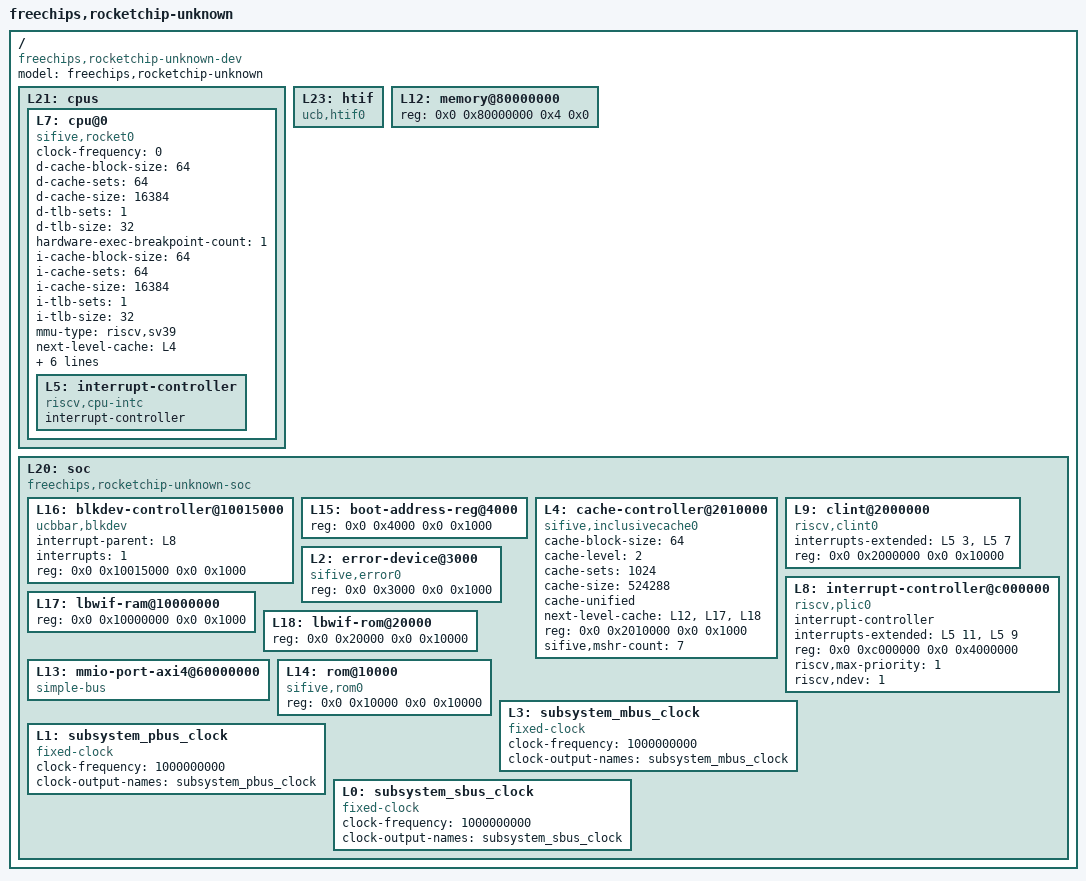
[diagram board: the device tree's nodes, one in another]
/dts-v1/;

/ {
	#address-cells = <2>;
	#size-cells = <2>;
	compatible = "freechips,rocketchip-unknown-dev";
	model = "freechips,rocketchip-unknown";
	L21: cpus {
		#address-cells = <1>;
		#size-cells = <0>;
		L7: cpu@0 {
			clock-frequency = <0>;
			compatible = "sifive,rocket0", "riscv";
			d-cache-block-size = <64>;
			d-cache-sets = <64>;
			d-cache-size = <16384>;
			d-tlb-sets = <1>;
			d-tlb-size = <32>;
			device_type = "cpu";
			hardware-exec-breakpoint-count = <1>;
			i-cache-block-size = <64>;
			i-cache-sets = <64>;
			i-cache-size = <16384>;
			i-tlb-sets = <1>;
			i-tlb-size = <32>;
			mmu-type = "riscv,sv39";
			next-level-cache = <&L4>;
			reg = <0x0>;
			riscv,isa = "rv64imafdc";
			riscv,pmpgranularity = <4>;
			riscv,pmpregions = <8>;
			status = "okay";
			timebase-frequency = <1000000>;
			tlb-split;
			L5: interrupt-controller {
				#interrupt-cells = <1>;
				compatible = "riscv,cpu-intc";
				interrupt-controller;
			};
		};
	};
	L23: htif {
		compatible = "ucb,htif0";
	};
	L12: memory@80000000 {
		device_type = "memory";
		reg = <0x0 0x80000000 0x4 0x0>;
	};
	L20: soc {
		#address-cells = <2>;
		#size-cells = <2>;
		compatible = "freechips,rocketchip-unknown-soc", "simple-bus";
		ranges;
		L16: blkdev-controller@10015000 {
			compatible = "ucbbar,blkdev";
			interrupt-parent = <&L8>;
			interrupts = <1>;
			reg = <0x0 0x10015000 0x0 0x1000>;
			reg-names = "control";
		};
		L15: boot-address-reg@4000 {
			reg = <0x0 0x4000 0x0 0x1000>;
			reg-names = "control";
		};
		L4: cache-controller@2010000 {
			cache-block-size = <64>;
			cache-level = <2>;
			cache-sets = <1024>;
			cache-size = <524288>;
			cache-unified;
			compatible = "sifive,inclusivecache0", "cache";
			next-level-cache = <&L12 &L17 &L18>;
			reg = <0x0 0x2010000 0x0 0x1000>;
			reg-names = "control";
			sifive,mshr-count = <7>;
		};
		L9: clint@2000000 {
			compatible = "riscv,clint0";
			interrupts-extended = <&L5 3 &L5 7>;
			reg = <0x0 0x2000000 0x0 0x10000>;
			reg-names = "control";
		};
		L2: error-device@3000 {
			compatible = "sifive,error0";
			reg = <0x0 0x3000 0x0 0x1000>;
		};
		L8: interrupt-controller@c000000 {
			#interrupt-cells = <1>;
			compatible = "riscv,plic0";
			interrupt-controller;
			interrupts-extended = <&L5 11 &L5 9>;
			reg = <0x0 0xc000000 0x0 0x4000000>;
			reg-names = "control";
			riscv,max-priority = <1>;
			riscv,ndev = <1>;
		};
		L17: lbwif-ram@10000000 {
			reg = <0x0 0x10000000 0x0 0x1000>;
		};
		L18: lbwif-rom@20000 {
			reg = <0x0 0x20000 0x0 0x10000>;
		};
		L13: mmio-port-axi4@60000000 {
			#address-cells = <1>;
			#size-cells = <1>;
			compatible = "simple-bus";
			ranges = <0x60000000 0x0 0x60000000 0x20000000>;
		};
		L14: rom@10000 {
			compatible = "sifive,rom0";
			reg = <0x0 0x10000 0x0 0x10000>;
			reg-names = "mem";
		};
		L3: subsystem_mbus_clock {
			#clock-cells = <0>;
			clock-frequency = <1000000000>;
			clock-output-names = "subsystem_mbus_clock";
			compatible = "fixed-clock";
		};
		L1: subsystem_pbus_clock {
			#clock-cells = <0>;
			clock-frequency = <1000000000>;
			clock-output-names = "subsystem_pbus_clock";
			compatible = "fixed-clock";
		};
		L0: subsystem_sbus_clock {
			#clock-cells = <0>;
			clock-frequency = <1000000000>;
			clock-output-names = "subsystem_sbus_clock";
			compatible = "fixed-clock";
		};
	};
};
